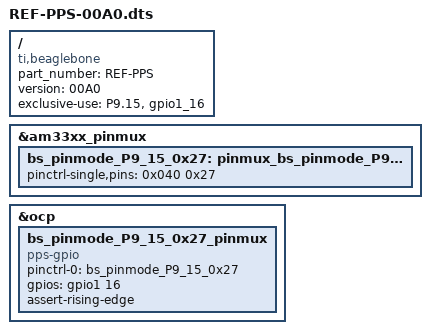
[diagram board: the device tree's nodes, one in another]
/dts-v1/;
/plugin/;

/{
    compatible = "ti,beaglebone", "ti,beaglebone-black";
    part_number = "REF-PPS";
    version = "00A0";

    exclusive-use =
        "P9.15",
        "gpio1_16";

    fragment@0 {
        target = <&am33xx_pinmux>;
        __overlay__ {
            bs_pinmode_P9_15_0x27: pinmux_bs_pinmode_P9_15_0x27 {
                pinctrl-single,pins = <0x040 0x27>;
            };
        };
    };

    fragment@1 {
        target = <&ocp>;
        __overlay__ {
            bs_pinmode_P9_15_0x27_pinmux {
                compatible = "pps-gpio";
                status = "okay";
                pinctrl-names = "default";
                pinctrl-0 = <&bs_pinmode_P9_15_0x27>;
                gpios = <&gpio1 16 0>; /* gpio2 for 1-based counting, gpio1 for 0-based */
                assert-rising-edge;
            };
        };
    };
};

